AUTOSAR XML (schema 4-0-3)
package /DTC_Component
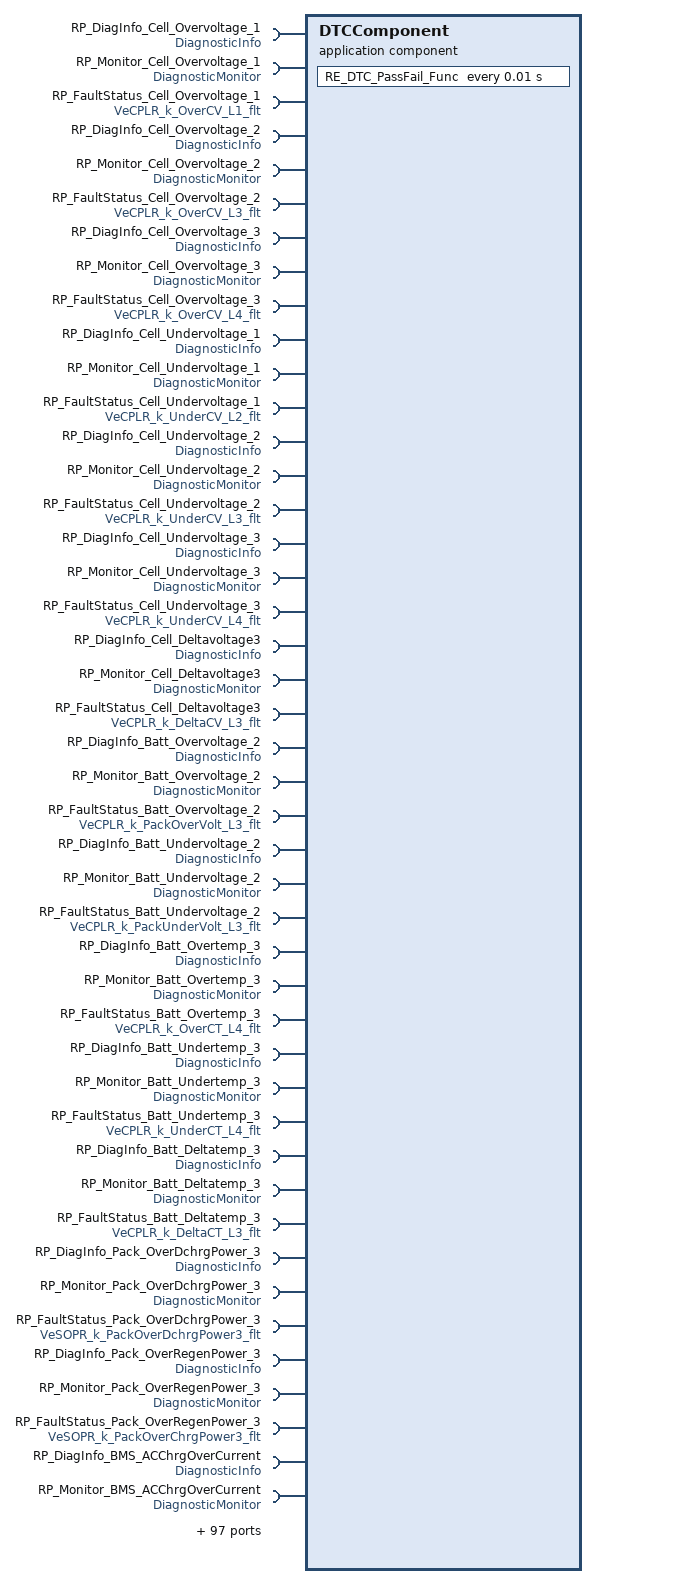
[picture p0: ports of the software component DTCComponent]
  application sw component type DTCComponent
    141 x require port:
      RP_DiagInfo_Cell_Overvoltage_1: required-interface=DiagnosticInfo
      RP_Monitor_Cell_Overvoltage_1: required-interface=DiagnosticMonitor
      RP_FaultStatus_Cell_Overvoltage_1: required-interface=VeCPLR_k_OverCV_L1_flt
      RP_DiagInfo_Cell_Overvoltage_2: required-interface=DiagnosticInfo
      RP_Monitor_Cell_Overvoltage_2: required-interface=DiagnosticMonitor
      RP_FaultStatus_Cell_Overvoltage_2: required-interface=VeCPLR_k_OverCV_L3_flt
      RP_DiagInfo_Cell_Overvoltage_3: required-interface=DiagnosticInfo
      RP_Monitor_Cell_Overvoltage_3: required-interface=DiagnosticMonitor
      RP_FaultStatus_Cell_Overvoltage_3: required-interface=VeCPLR_k_OverCV_L4_flt
      RP_DiagInfo_Cell_Undervoltage_1: required-interface=DiagnosticInfo
      RP_Monitor_Cell_Undervoltage_1: required-interface=DiagnosticMonitor
      RP_FaultStatus_Cell_Undervoltage_1: required-interface=VeCPLR_k_UnderCV_L2_flt
      RP_DiagInfo_Cell_Undervoltage_2: required-interface=DiagnosticInfo
      RP_Monitor_Cell_Undervoltage_2: required-interface=DiagnosticMonitor
      RP_FaultStatus_Cell_Undervoltage_2: required-interface=VeCPLR_k_UnderCV_L3_flt
      RP_DiagInfo_Cell_Undervoltage_3: required-interface=DiagnosticInfo
      RP_Monitor_Cell_Undervoltage_3: required-interface=DiagnosticMonitor
      RP_FaultStatus_Cell_Undervoltage_3: required-interface=VeCPLR_k_UnderCV_L4_flt
      RP_DiagInfo_Cell_Deltavoltage3: required-interface=DiagnosticInfo
      RP_Monitor_Cell_Deltavoltage3: required-interface=DiagnosticMonitor
      RP_FaultStatus_Cell_Deltavoltage3: required-interface=VeCPLR_k_DeltaCV_L3_flt
      RP_DiagInfo_Batt_Overvoltage_2: required-interface=DiagnosticInfo
      RP_Monitor_Batt_Overvoltage_2: required-interface=DiagnosticMonitor
      RP_FaultStatus_Batt_Overvoltage_2: required-interface=VeCPLR_k_PackOverVolt_L3_flt
      RP_DiagInfo_Batt_Undervoltage_2: required-interface=DiagnosticInfo
      RP_Monitor_Batt_Undervoltage_2: required-interface=DiagnosticMonitor
      RP_FaultStatus_Batt_Undervoltage_2: required-interface=VeCPLR_k_PackUnderVolt_L3_flt
      RP_DiagInfo_Batt_Overtemp_3: required-interface=DiagnosticInfo
      RP_Monitor_Batt_Overtemp_3: required-interface=DiagnosticMonitor
      RP_FaultStatus_Batt_Overtemp_3: required-interface=VeCPLR_k_OverCT_L4_flt
      RP_DiagInfo_Batt_Undertemp_3: required-interface=DiagnosticInfo
      RP_Monitor_Batt_Undertemp_3: required-interface=DiagnosticMonitor
      RP_FaultStatus_Batt_Undertemp_3: required-interface=VeCPLR_k_UnderCT_L4_flt
      RP_DiagInfo_Batt_Deltatemp_3: required-interface=DiagnosticInfo
      RP_Monitor_Batt_Deltatemp_3: required-interface=DiagnosticMonitor
      RP_FaultStatus_Batt_Deltatemp_3: required-interface=VeCPLR_k_DeltaCT_L3_flt
      RP_DiagInfo_Pack_OverDchrgPower_3: required-interface=DiagnosticInfo
      RP_Monitor_Pack_OverDchrgPower_3: required-interface=DiagnosticMonitor
      RP_FaultStatus_Pack_OverDchrgPower_3: required-interface=VeSOPR_k_PackOverDchrgPower3_flt
      RP_DiagInfo_Pack_OverRegenPower_3: required-interface=DiagnosticInfo
      RP_Monitor_Pack_OverRegenPower_3: required-interface=DiagnosticMonitor
      RP_FaultStatus_Pack_OverRegenPower_3: required-interface=VeSOPR_k_PackOverChrgPower3_flt
      RP_DiagInfo_BMS_ACChrgOverCurrent: required-interface=DiagnosticInfo
      RP_Monitor_BMS_ACChrgOverCurrent: required-interface=DiagnosticMonitor
      RP_FaultStatus_BMS_ACChrgOverCurrent: required-interface=VeCHMR_k_ChrgOverCurr_level3_flt
      RP_DiagInfo_SOC_low_3: required-interface=DiagnosticInfo
      RP_Monitor_SOC_low_3: required-interface=DiagnosticMonitor
      RP_FaultStatus_SOC_low_3: required-interface=VeSOCR_k_SOC_low3_flt
      RP_DiagInfo_IsoResistor_Error_1: required-interface=DiagnosticInfo
      RP_Monitor_IsoResistor_Error_1: required-interface=DiagnosticMonitor
      RP_FaultStatus_IsoResistor_Error_1: required-interface=VeISLR_k_Isolation_L1_flt
      RP_DiagInfo_IsoResistor_Error_2: required-interface=DiagnosticInfo
      RP_Monitor_IsoResistor_Error_2: required-interface=DiagnosticMonitor
      RP_FaultStatus_IsoResistor_Error_2: required-interface=VeISLR_k_Isolation_L2_flt
      RP_DiagInfo_Crash_states: required-interface=DiagnosticInfo
      RP_Monitor_Crash_states: required-interface=DiagnosticMonitor
      RP_DiagInfo_ThermalRunaway_Error: required-interface=DiagnosticInfo
      RP_Monitor_ThermalRunaway_Error: required-interface=DiagnosticMonitor
      RP_FaultStatus_ThermalRunaway_Error: required-interface=VeCPLR_k_ThermalRunaway_flt
      RP_DiagInfo_BatteryHeatingFault: required-interface=DiagnosticInfo
      RP_Monitor_BatteryHeatingFault: required-interface=DiagnosticMonitor
      RP_FaultStatus_BatteryHeatingFault: required-interface=VeTHMR_k_BatteryHeatingOverCurrt_flt
      RP_DiagInfo_BatteryCoolingFault: required-interface=DiagnosticInfo
      RP_Monitor_BatteryCoolingFault: required-interface=DiagnosticMonitor
      RP_FaultStatus_BatteryCoolingFault: required-interface=VeTHMR_k_BatteryCooling_flt
      RP_DiagInfo_BatteryCircuitOverCurrent: required-interface=DiagnosticInfo
      RP_Monitor_BatteryCircuitOverCurrent: required-interface=DiagnosticMonitor
      RP_FaultStatus_BatteryCircuitOverCurrent: required-interface=VeVSDR_k_HVOverCurrent_flt
      RP_DiagInfo_PosCont_StuckClose: required-interface=DiagnosticInfo
      RP_Monitor_PosCont_StuckClose: required-interface=DiagnosticMonitor
      RP_FaultStatus_PosCont_StuckClose: required-interface=VeCFLR_k_PositiveStuckClose_flt
      RP_DiagInfo_PosCont_StuckOpen: required-interface=DiagnosticInfo
      RP_Monitor_PosCont_StuckOpen: required-interface=DiagnosticMonitor
      RP_FaultStatus_PosCont_StuckOpen: required-interface=VeCFLR_k_PositiveStuckOpen_flt
      RP_DiagInfo_NegCont_StuckClose: required-interface=DiagnosticInfo
      RP_Monitor_NegCont_StuckClose: required-interface=DiagnosticMonitor
      RP_FaultStatus_NegCont_StuckClose: required-interface=VeCFLR_k_NegativeStuckClose_flt
      RP_DiagInfo_NegCont_StuckOpen: required-interface=DiagnosticInfo
      RP_Monitor_NegCont_StuckOpen: required-interface=DiagnosticMonitor
      RP_FaultStatus_NegCont_StuckOpen: required-interface=VeCFLR_k_NegativeStuckOpen_flt
      RP_DiagInfo_PrechrgCont_StuckClose: required-interface=DiagnosticInfo
      RP_Monitor_PrechrgCont_StuckClose: required-interface=DiagnosticMonitor
      RP_FaultStatus_PrechrgCont_StuckClose: required-interface=VeCFLR_k_PrechargeStuckClose_flt
      RP_DiagInfo_PrechrgCont_StuckOpen: required-interface=DiagnosticInfo
      RP_Monitor_PrechrgCont_StuckOpen: required-interface=DiagnosticMonitor
      RP_FaultStatus_PrechrgCont_StuckOpen: required-interface=VeCFLR_k_PrechargeStuckOpen_flt
      RP_DiagInfo_MainFuse1_Open: required-interface=DiagnosticInfo
      RP_Monitor_MainFuse1_Open: required-interface=DiagnosticMonitor
      RP_FaultStatus_MainFuse1_Open: required-interface=VeCFLR_k_MainFuse1Open_flt
      RP_DiagInfo_MainFuse2_Open: required-interface=DiagnosticInfo
      RP_Monitor_MainFuse2_Open: required-interface=DiagnosticMonitor
      RP_FaultStatus_MainFuse2_Open: required-interface=VeCFLR_k_MainFuse2Open_flt
      RP_DiagInfo_VehicleHVInterlockError: required-interface=DiagnosticInfo
      RP_Monitor_VehicleHVInterlockError: required-interface=DiagnosticMonitor
      RP_FaultStatus_VehicleHVInterlockError: required-interface=VeHVIR_k_MainHVIL2_flt
      RP_DiagInfo_BatteryHVInterlockError: required-interface=DiagnosticInfo
      RP_Monitor_BatteryHVInterlockError: required-interface=DiagnosticMonitor
      RP_FaultStatus_BatteryHVInterlockError: required-interface=VeHVIR_k_MainHVIL_flt
      RP_DiagInfo_BatteryInsulationFault: required-interface=DiagnosticInfo
      RP_Monitor_BatteryInsulationFault: required-interface=DiagnosticMonitor
      RP_FaultStatus_BatteryInsulationFault: required-interface=VeISLR_InterIsolation_flt
      RP_DiagInfo_VehicleInsulationFault: required-interface=DiagnosticInfo
      RP_Monitor_VehicleInsulationFault: required-interface=DiagnosticMonitor
      RP_FaultStatus_VehicleInsulationFault: required-interface=VeISLR_ExterIsolation_flt
      RP_DiagInfo_Precharge_Resistor_Open: required-interface=DiagnosticInfo
      RP_Monitor_Precharge_Resistor_Open: required-interface=DiagnosticMonitor
      RP_FaultStatus_Precharge_Resistor_Open: required-interface=VeCFLR_k_PreResistorStuckOpen_flt
      RP_DiagInfo_Precharge_Error: required-interface=DiagnosticInfo
      RP_Monitor_Precharge_Error: required-interface=DiagnosticMonitor
      RP_FaultStatus_Precharge_Error: required-interface=VeCFLR_k_PreChargeFail_flt
      RP_DiagInfo_PrechargeShortCircuit: required-interface=DiagnosticInfo
      RP_Monitor_PrechargeShortCircuit: required-interface=DiagnosticMonitor
      RP_FaultStatus_PrechargeShortCircuit: required-interface=VeCFLR_k_PreChargeOvCur_flt
      RP_DiagInfo_CAN_VCU_error: required-interface=DiagnosticInfo
      RP_Monitor_CAN_VCU_error: required-interface=DiagnosticMonitor
      RP_DiagInfo_CAN_MCUF_Error: required-interface=DiagnosticInfo
      RP_Monitor_CAN_MCUF_Error: required-interface=DiagnosticMonitor
      RP_DiagInfo_CAN_MCUR_Error: required-interface=DiagnosticInfo
      RP_Monitor_CAN_MCUR_Error: required-interface=DiagnosticMonitor
      RP_DiagInfo_CAN_ISG_Error: required-interface=DiagnosticInfo
      RP_Monitor_CAN_ISG_Error: required-interface=DiagnosticMonitor
      RP_DiagInfo_CAN_CDU_Error: required-interface=DiagnosticInfo
      RP_Monitor_CAN_CDU_Error: required-interface=DiagnosticMonitor
      RP_DiagInfo_CAN_CLM_Error: required-interface=DiagnosticInfo
      RP_Monitor_CAN_CLM_Error: required-interface=DiagnosticMonitor
      RP_DiagInfo_CAN_ABM_Error: required-interface=DiagnosticInfo
      RP_Monitor_CAN_ABM_Error: required-interface=DiagnosticMonitor
      RP_DiagInfo_CAN_ICM_Error: required-interface=DiagnosticInfo
      RP_Monitor_CAN_ICM_Error: required-interface=DiagnosticMonitor
      RP_DiagInfo_CAN_TBOX_Error: required-interface=DiagnosticInfo
      RP_Monitor_CAN_TBOX_Error: required-interface=DiagnosticMonitor
      RP_DiagInfo_CAN_BSM_Error: required-interface=DiagnosticInfo
      RP_Monitor_CAN_BSM_Error: required-interface=DiagnosticMonitor
      RP_DiagInfo_CAN_EMS_Error: required-interface=DiagnosticInfo
      RP_Monitor_CAN_EMS_Error: required-interface=DiagnosticMonitor
      RP_DiagInfo_PTCAN_BusOff: required-interface=DiagnosticInfo
      RP_Monitor_PTCAN_BusOff: required-interface=DiagnosticMonitor
      RP_DiagInfo_LV_UnderVoltage: required-interface=DiagnosticInfo
      RP_Monitor_LV_UnderVoltage: required-interface=DiagnosticMonitor
      RP_DiagInfo_LV_OverVoltage: required-interface=DiagnosticInfo
      RP_Monitor_LV_OverVoltage: required-interface=DiagnosticMonitor
    behavior IB_DTC_Cmpnt: data-type-mapping=[VSDR_CodeDataTypeMappingsSet, CLBR_CodeDataTypeMappingsSet, SOER_CodeDataTypeMappingsSet, WorkingDataTypeMappingsSet, ADPR_CodeDataTypeMappingsSet, CHMR_CodeDataTypeMappingsSet, IoHwAbs_CodeDataTypeMappingsSet, THMR_CodeDataTypeMappingsSet, SOPR_CodeDataTypeMappingsSet, CSCR_CodeDataTypeMappingsSet, HMIR_CodeDataTypeMappingsSet, CFLR_CodeDataTypeMappingsSet, DHSR_CodeDataTypeMappingsSet, CPLR_CodeDataTypeMappingsSet, ISLR_CodeDataTypeMappingsSet, DataTypeMappingSet_E2E, SOCR_CodeDataTypeMappingsSet, SOHR_CodeDataTypeMappingsSet, HVSR_CodeDataTypeMappingsSet, HVIR_CodeDataTypeMappingsSet, RTCR_CodeDataTypeMappingSet]
      timing event TimingEvent_DTCs: start-on-event=RE_DTC_PassFail_Func, period=0.01
      runnable RE_DTC_PassFail_Func: symbol=DTC_PassFail_Func
        data-read-access:
          37 x access:
            DRA_VeCPLR_k_OverCV_L1_flt_0: accessed-variable=RP_FaultStatus_Cell_Overvoltage_1.VeCPLR_k_OverCV_L1_flt
            DRA_VeCPLR_k_OverCV_L3_flt_0: accessed-variable=RP_FaultStatus_Cell_Overvoltage_2.VeCPLR_k_OverCV_L3_flt
            DRA_VeCPLR_k_OverCV_L4_flt_0: accessed-variable=RP_FaultStatus_Cell_Overvoltage_3.VeCPLR_k_OverCV_L4_flt
            DRA_VeCPLR_k_UnderCV_L2_flt_0: accessed-variable=RP_FaultStatus_Cell_Undervoltage_1.VeCPLR_k_UnderCV_L2_flt
            DRA_VeCPLR_k_UnderCV_L3_flt_0: accessed-variable=RP_FaultStatus_Cell_Undervoltage_2.VeCPLR_k_UnderCV_L3_flt
            DRA_VeCPLR_k_UnderCV_L4_flt_0: accessed-variable=RP_FaultStatus_Cell_Undervoltage_3.VeCPLR_k_UnderCV_L4_flt
            DRA_VeCPLR_k_DeltaCV_L3_flt_0: accessed-variable=RP_FaultStatus_Cell_Deltavoltage3.VeCPLR_k_DeltaCV_L3_flt
            DRA_VeCPLR_k_PackOverVolt_L3_flt_0: accessed-variable=RP_FaultStatus_Batt_Overvoltage_2.VeCPLR_k_PackOverVolt_L3_flt
            DRA_VeCPLR_k_PackUnderVolt_L3_flt_0: accessed-variable=RP_FaultStatus_Batt_Undervoltage_2.VeCPLR_k_PackUnderVolt_L3_flt
            DRA_VeCPLR_k_OverCT_L4_flt_0: accessed-variable=RP_FaultStatus_Batt_Overtemp_3.VeCPLR_k_OverCT_L4_flt
            DRA_VeCPLR_k_UnderCT_L4_flt_0: accessed-variable=RP_FaultStatus_Batt_Undertemp_3.VeCPLR_k_UnderCT_L4_flt
            DRA_VeCPLR_k_DeltaCT_L3_flt_0: accessed-variable=RP_FaultStatus_Batt_Deltatemp_3.VeCPLR_k_DeltaCT_L3_flt
            DRA_VeSOPR_k_PackOverDchrgPower3_flt_0: accessed-variable=RP_FaultStatus_Pack_OverDchrgPower_3.VeSOPR_k_PackOverDchrgPower3_flt
            DRA_VeSOPR_k_PackOverChrgPower3_flt_0: accessed-variable=RP_FaultStatus_Pack_OverRegenPower_3.VeSOPR_k_PackOverChrgPower3_flt
            DRA_VeCHMR_k_ChrgOverCurr_level3_flt_0: accessed-variable=RP_FaultStatus_BMS_ACChrgOverCurrent.VeCHMR_k_ChrgOverCurr_level3_flt
            DRA_VeSOCR_k_SOC_low3_flt_0: accessed-variable=RP_FaultStatus_SOC_low_3.VeSOCR_k_SOC_low3_flt
            DRA_VeISLR_k_Isolation_L1_flt_0: accessed-variable=RP_FaultStatus_IsoResistor_Error_1.VeISLR_k_Isolation_L1_flt
            DRA_VeISLR_k_Isolation_L2_flt_0: accessed-variable=RP_FaultStatus_IsoResistor_Error_2.VeISLR_k_Isolation_L2_flt
            DRA_VeCPLR_k_ThermalRunaway_flt_0: accessed-variable=RP_FaultStatus_ThermalRunaway_Error.VeCPLR_k_ThermalRunaway_flt
            DRA_VeTHMR_k_BatteryHeatingOverCurrt_flt_0: accessed-variable=RP_FaultStatus_BatteryHeatingFault.VeTHMR_k_BatteryHeatingOverCurrt_flt
            DRA_VeTHMR_k_BatteryCooling_flt_0: accessed-variable=RP_FaultStatus_BatteryCoolingFault.VeTHMR_k_BatteryCooling_flt
            DRA_VeVSDR_k_HVOverCurrent_flt_0: accessed-variable=RP_FaultStatus_BatteryCircuitOverCurrent.VeVSDR_k_HVOverCurrent_flt
            DRA_VeCFLR_k_PositiveStuckClose_flt_0: accessed-variable=RP_FaultStatus_PosCont_StuckClose.VeCFLR_k_PositiveStuckClose_flt
            DRA_VeCFLR_k_PositiveStuckOpen_flt_0: accessed-variable=RP_FaultStatus_PosCont_StuckOpen.VeCFLR_k_PositiveStuckOpen_flt
            DRA_VeCFLR_k_NegativeStuckClose_flt_0: accessed-variable=RP_FaultStatus_NegCont_StuckClose.VeCFLR_k_NegativeStuckClose_flt
            DRA_VeCFLR_k_NegativeStuckOpen_flt_0: accessed-variable=RP_FaultStatus_NegCont_StuckOpen.VeCFLR_k_NegativeStuckOpen_flt
            DRA_VeCFLR_k_PrechargeStuckClose_flt_0: accessed-variable=RP_FaultStatus_PrechrgCont_StuckClose.VeCFLR_k_PrechargeStuckClose_flt
            DRA_VeCFLR_k_PrechargeStuckOpen_flt_0: accessed-variable=RP_FaultStatus_PrechrgCont_StuckOpen.VeCFLR_k_PrechargeStuckOpen_flt
            DRA_VeCFLR_k_MainFuse1Open_flt_0: accessed-variable=RP_FaultStatus_MainFuse1_Open.VeCFLR_k_MainFuse1Open_flt
            DRA_VeCFLR_k_MainFuse2Open_flt_0: accessed-variable=RP_FaultStatus_MainFuse2_Open.VeCFLR_k_MainFuse2Open_flt
            DRA_VeHVIR_k_MainHVIL2_flt_0: accessed-variable=RP_FaultStatus_VehicleHVInterlockError.VeHVIR_k_MainHVIL2_flt
            DRA_VeHVIR_k_MainHVIL_flt_0: accessed-variable=RP_FaultStatus_BatteryHVInterlockError.VeHVIR_k_MainHVIL_flt
            DRA_VeISLR_InterIsolation_flt_0: accessed-variable=RP_FaultStatus_BatteryInsulationFault.VeISLR_InterIsolation_flt
            DRA_VeISLR_ExterIsolation_flt_0: accessed-variable=RP_FaultStatus_VehicleInsulationFault.VeISLR_ExterIsolation_flt
            DRA_VeCFLR_k_PreResistorStuckOpen_flt_0: accessed-variable=RP_FaultStatus_Precharge_Resistor_Open.VeCFLR_k_PreResistorStuckOpen_flt
            DRA_VeCFLR_k_PreChargeFail_flt_0: accessed-variable=RP_FaultStatus_Precharge_Error.VeCFLR_k_PreChargeFail_flt
            DRA_VeCFLR_k_PreChargeOvCur_flt_0: accessed-variable=RP_FaultStatus_PrechargeShortCircuit.VeCFLR_k_PreChargeOvCur_flt
        468 x sync call:
          SSCP_GES_Cell_Overvoltage_1: operation=RP_DiagInfo_Cell_Overvoltage_1.GetEventStatus
          SSCP_GEF_Cell_Overvoltage_1: operation=RP_DiagInfo_Cell_Overvoltage_1.GetEventFailed
          SSCP_GET_Cell_Overvoltage_1: operation=RP_DiagInfo_Cell_Overvoltage_1.GetEventTested
          SSCP_GDTC_Cell_Overvoltage_1: operation=RP_DiagInfo_Cell_Overvoltage_1.GetDTCOfEvent
          SSCP_GFDC_Cell_Overvoltage_1: operation=RP_DiagInfo_Cell_Overvoltage_1.GetFaultDetectionCounter
          SSCP_SES_Cell_Overvoltage_1: operation=RP_Monitor_Cell_Overvoltage_1.SetEventStatus
          SSCP_RES_Cell_Overvoltage_1: operation=RP_Monitor_Cell_Overvoltage_1.ResetEventStatus
          SSCP_PFF_Cell_Overvoltage_1: operation=RP_Monitor_Cell_Overvoltage_1.PrestoreFreezeFrame
          SSCP_CPFF_Cell_Overvoltage_1: operation=RP_Monitor_Cell_Overvoltage_1.ClearPrestoredFreezeFrame
          SSCP_GES_Cell_Overvoltage_2: operation=RP_DiagInfo_Cell_Overvoltage_2.GetEventStatus
          SSCP_GEF_Cell_Overvoltage_2: operation=RP_DiagInfo_Cell_Overvoltage_2.GetEventFailed
          SSCP_GET_Cell_Overvoltage_2: operation=RP_DiagInfo_Cell_Overvoltage_2.GetEventTested
          SSCP_GDTC_Cell_Overvoltage_2: operation=RP_DiagInfo_Cell_Overvoltage_2.GetDTCOfEvent
          SSCP_GFDC_Cell_Overvoltage_2: operation=RP_DiagInfo_Cell_Overvoltage_2.GetFaultDetectionCounter
          SSCP_SES_Cell_Overvoltage_2: operation=RP_Monitor_Cell_Overvoltage_2.SetEventStatus
          SSCP_RES_Cell_Overvoltage_2: operation=RP_Monitor_Cell_Overvoltage_2.ResetEventStatus
          SSCP_PFF_Cell_Overvoltage_2: operation=RP_Monitor_Cell_Overvoltage_2.PrestoreFreezeFrame
          SSCP_CPFF_Cell_Overvoltage_2: operation=RP_Monitor_Cell_Overvoltage_2.ClearPrestoredFreezeFrame
          SSCP_GES_Cell_Overvoltage_3: operation=RP_DiagInfo_Cell_Overvoltage_3.GetEventStatus
          SSCP_GEF_Cell_Overvoltage_3: operation=RP_DiagInfo_Cell_Overvoltage_3.GetEventFailed
          SSCP_GET_Cell_Overvoltage_3: operation=RP_DiagInfo_Cell_Overvoltage_3.GetEventTested
          SSCP_GDTC_Cell_Overvoltage_3: operation=RP_DiagInfo_Cell_Overvoltage_3.GetDTCOfEvent
          SSCP_GFDC_Cell_Overvoltage_3: operation=RP_DiagInfo_Cell_Overvoltage_3.GetFaultDetectionCounter
          SSCP_SES_Cell_Overvoltage_3: operation=RP_Monitor_Cell_Overvoltage_3.SetEventStatus
          SSCP_RES_Cell_Overvoltage_3: operation=RP_Monitor_Cell_Overvoltage_3.ResetEventStatus
          SSCP_PFF_Cell_Overvoltage_3: operation=RP_Monitor_Cell_Overvoltage_3.PrestoreFreezeFrame
          SSCP_CPFF_Cell_Overvoltage_3: operation=RP_Monitor_Cell_Overvoltage_3.ClearPrestoredFreezeFrame
          SSCP_GES_Cell_Undervoltage_1: operation=RP_DiagInfo_Cell_Undervoltage_1.GetEventStatus
          SSCP_GEF_Cell_Undervoltage_1: operation=RP_DiagInfo_Cell_Undervoltage_1.GetEventFailed
          SSCP_GET_Cell_Undervoltage_1: operation=RP_DiagInfo_Cell_Undervoltage_1.GetEventTested
          SSCP_GDTC_Cell_Undervoltage_1: operation=RP_DiagInfo_Cell_Undervoltage_1.GetDTCOfEvent
          SSCP_GFDC_Cell_Undervoltage_1: operation=RP_DiagInfo_Cell_Undervoltage_1.GetFaultDetectionCounter
          SSCP_SES_Cell_Undervoltage_1: operation=RP_Monitor_Cell_Undervoltage_1.SetEventStatus
          SSCP_RES_Cell_Undervoltage_1: operation=RP_Monitor_Cell_Undervoltage_1.ResetEventStatus
          SSCP_PFF_Cell_Undervoltage_1: operation=RP_Monitor_Cell_Undervoltage_1.PrestoreFreezeFrame
          SSCP_CPFF_Cell_Undervoltage_1: operation=RP_Monitor_Cell_Undervoltage_1.ClearPrestoredFreezeFrame
          SSCP_GES_Cell_Undervoltage_2: operation=RP_DiagInfo_Cell_Undervoltage_2.GetEventStatus
          SSCP_GEF_Cell_Undervoltage_2: operation=RP_DiagInfo_Cell_Undervoltage_2.GetEventFailed
          SSCP_GET_Cell_Undervoltage_2: operation=RP_DiagInfo_Cell_Undervoltage_2.GetEventTested
          SSCP_GDTC_Cell_Undervoltage_2: operation=RP_DiagInfo_Cell_Undervoltage_2.GetDTCOfEvent
          SSCP_GFDC_Cell_Undervoltage_2: operation=RP_DiagInfo_Cell_Undervoltage_2.GetFaultDetectionCounter
          SSCP_SES_Cell_Undervoltage_2: operation=RP_Monitor_Cell_Undervoltage_2.SetEventStatus
          SSCP_RES_Cell_Undervoltage_2: operation=RP_Monitor_Cell_Undervoltage_2.ResetEventStatus
          SSCP_PFF_Cell_Undervoltage_2: operation=RP_Monitor_Cell_Undervoltage_2.PrestoreFreezeFrame
          SSCP_CPFF_Cell_Undervoltage_2: operation=RP_Monitor_Cell_Undervoltage_2.ClearPrestoredFreezeFrame
          SSCP_GES_Cell_Undervoltage_3: operation=RP_DiagInfo_Cell_Undervoltage_3.GetEventStatus
          SSCP_GEF_Cell_Undervoltage_3: operation=RP_DiagInfo_Cell_Undervoltage_3.GetEventFailed
          SSCP_GET_Cell_Undervoltage_3: operation=RP_DiagInfo_Cell_Undervoltage_3.GetEventTested
          SSCP_GDTC_Cell_Undervoltage_3: operation=RP_DiagInfo_Cell_Undervoltage_3.GetDTCOfEvent
          SSCP_GFDC_Cell_Undervoltage_3: operation=RP_DiagInfo_Cell_Undervoltage_3.GetFaultDetectionCounter
          SSCP_SES_Cell_Undervoltage_3: operation=RP_Monitor_Cell_Undervoltage_3.SetEventStatus
          SSCP_RES_Cell_Undervoltage_3: operation=RP_Monitor_Cell_Undervoltage_3.ResetEventStatus
          SSCP_PFF_Cell_Undervoltage_3: operation=RP_Monitor_Cell_Undervoltage_3.PrestoreFreezeFrame
          SSCP_CPFF_Cell_Undervoltage_3: operation=RP_Monitor_Cell_Undervoltage_3.ClearPrestoredFreezeFrame
          SSCP_GES_Cell_Deltavoltage3: operation=RP_DiagInfo_Cell_Deltavoltage3.GetEventStatus
          SSCP_GEF_Cell_Deltavoltage3: operation=RP_DiagInfo_Cell_Deltavoltage3.GetEventFailed
          SSCP_GET_Cell_Deltavoltage3: operation=RP_DiagInfo_Cell_Deltavoltage3.GetEventTested
          SSCP_GDTC_Cell_Deltavoltage3: operation=RP_DiagInfo_Cell_Deltavoltage3.GetDTCOfEvent
          SSCP_GFDC_Cell_Deltavoltage3: operation=RP_DiagInfo_Cell_Deltavoltage3.GetFaultDetectionCounter
          SSCP_SES_Cell_Deltavoltage3: operation=RP_Monitor_Cell_Deltavoltage3.SetEventStatus
          SSCP_RES_Cell_Deltavoltage3: operation=RP_Monitor_Cell_Deltavoltage3.ResetEventStatus
          SSCP_PFF_Cell_Deltavoltage3: operation=RP_Monitor_Cell_Deltavoltage3.PrestoreFreezeFrame
          SSCP_CPFF_Cell_Deltavoltage3: operation=RP_Monitor_Cell_Deltavoltage3.ClearPrestoredFreezeFrame
          SSCP_GES_Batt_Overvoltage_2: operation=RP_DiagInfo_Batt_Overvoltage_2.GetEventStatus
          SSCP_GEF_Batt_Overvoltage_2: operation=RP_DiagInfo_Batt_Overvoltage_2.GetEventFailed
          SSCP_GET_Batt_Overvoltage_2: operation=RP_DiagInfo_Batt_Overvoltage_2.GetEventTested
          SSCP_GDTC_Batt_Overvoltage_2: operation=RP_DiagInfo_Batt_Overvoltage_2.GetDTCOfEvent
          SSCP_GFDC_Batt_Overvoltage_2: operation=RP_DiagInfo_Batt_Overvoltage_2.GetFaultDetectionCounter
          SSCP_SES_Batt_Overvoltage_2: operation=RP_Monitor_Batt_Overvoltage_2.SetEventStatus
          SSCP_RES_Batt_Overvoltage_2: operation=RP_Monitor_Batt_Overvoltage_2.ResetEventStatus
          SSCP_PFF_Batt_Overvoltage_2: operation=RP_Monitor_Batt_Overvoltage_2.PrestoreFreezeFrame
          SSCP_CPFF_Batt_Overvoltage_2: operation=RP_Monitor_Batt_Overvoltage_2.ClearPrestoredFreezeFrame
          SSCP_GES_Batt_Undervoltage_2: operation=RP_DiagInfo_Batt_Undervoltage_2.GetEventStatus
          SSCP_GEF_Batt_Undervoltage_2: operation=RP_DiagInfo_Batt_Undervoltage_2.GetEventFailed
          SSCP_GET_Batt_Undervoltage_2: operation=RP_DiagInfo_Batt_Undervoltage_2.GetEventTested
          SSCP_GDTC_Batt_Undervoltage_2: operation=RP_DiagInfo_Batt_Undervoltage_2.GetDTCOfEvent
          SSCP_GFDC_Batt_Undervoltage_2: operation=RP_DiagInfo_Batt_Undervoltage_2.GetFaultDetectionCounter
          SSCP_SES_Batt_Undervoltage_2: operation=RP_Monitor_Batt_Undervoltage_2.SetEventStatus
          SSCP_RES_Batt_Undervoltage_2: operation=RP_Monitor_Batt_Undervoltage_2.ResetEventStatus
          SSCP_PFF_Batt_Undervoltage_2: operation=RP_Monitor_Batt_Undervoltage_2.PrestoreFreezeFrame
          SSCP_CPFF_Batt_Undervoltage_2: operation=RP_Monitor_Batt_Undervoltage_2.ClearPrestoredFreezeFrame
          SSCP_GES_Batt_Overtemp_3: operation=RP_DiagInfo_Batt_Overtemp_3.GetEventStatus
          SSCP_GEF_Batt_Overtemp_3: operation=RP_DiagInfo_Batt_Overtemp_3.GetEventFailed
          SSCP_GET_Batt_Overtemp_3: operation=RP_DiagInfo_Batt_Overtemp_3.GetEventTested
          SSCP_GDTC_Batt_Overtemp_3: operation=RP_DiagInfo_Batt_Overtemp_3.GetDTCOfEvent
          SSCP_GFDC_Batt_Overtemp_3: operation=RP_DiagInfo_Batt_Overtemp_3.GetFaultDetectionCounter
          SSCP_SES_Batt_Overtemp_3: operation=RP_Monitor_Batt_Overtemp_3.SetEventStatus
          SSCP_RES_Batt_Overtemp_3: operation=RP_Monitor_Batt_Overtemp_3.ResetEventStatus
          SSCP_PFF_Batt_Overtemp_3: operation=RP_Monitor_Batt_Overtemp_3.PrestoreFreezeFrame
          SSCP_CPFF_Batt_Overtemp_3: operation=RP_Monitor_Batt_Overtemp_3.ClearPrestoredFreezeFrame
          SSCP_GES_Batt_Undertemp_3: operation=RP_DiagInfo_Batt_Undertemp_3.GetEventStatus
          SSCP_GEF_Batt_Undertemp_3: operation=RP_DiagInfo_Batt_Undertemp_3.GetEventFailed
          SSCP_GET_Batt_Undertemp_3: operation=RP_DiagInfo_Batt_Undertemp_3.GetEventTested
          SSCP_GDTC_Batt_Undertemp_3: operation=RP_DiagInfo_Batt_Undertemp_3.GetDTCOfEvent
          SSCP_GFDC_Batt_Undertemp_3: operation=RP_DiagInfo_Batt_Undertemp_3.GetFaultDetectionCounter
          SSCP_SES_Batt_Undertemp_3: operation=RP_Monitor_Batt_Undertemp_3.SetEventStatus
          SSCP_RES_Batt_Undertemp_3: operation=RP_Monitor_Batt_Undertemp_3.ResetEventStatus
          SSCP_PFF_Batt_Undertemp_3: operation=RP_Monitor_Batt_Undertemp_3.PrestoreFreezeFrame
          SSCP_CPFF_Batt_Undertemp_3: operation=RP_Monitor_Batt_Undertemp_3.ClearPrestoredFreezeFrame
          SSCP_GES_Batt_Deltatemp_3: operation=RP_DiagInfo_Batt_Deltatemp_3.GetEventStatus
          SSCP_GEF_Batt_Deltatemp_3: operation=RP_DiagInfo_Batt_Deltatemp_3.GetEventFailed
          SSCP_GET_Batt_Deltatemp_3: operation=RP_DiagInfo_Batt_Deltatemp_3.GetEventTested
          SSCP_GDTC_Batt_Deltatemp_3: operation=RP_DiagInfo_Batt_Deltatemp_3.GetDTCOfEvent
          SSCP_GFDC_Batt_Deltatemp_3: operation=RP_DiagInfo_Batt_Deltatemp_3.GetFaultDetectionCounter
          SSCP_SES_Batt_Deltatemp_3: operation=RP_Monitor_Batt_Deltatemp_3.SetEventStatus
          SSCP_RES_Batt_Deltatemp_3: operation=RP_Monitor_Batt_Deltatemp_3.ResetEventStatus
          SSCP_PFF_Batt_Deltatemp_3: operation=RP_Monitor_Batt_Deltatemp_3.PrestoreFreezeFrame
          SSCP_CPFF_Batt_Deltatemp_3: operation=RP_Monitor_Batt_Deltatemp_3.ClearPrestoredFreezeFrame
          SSCP_GES_Pack_OverDchrgPower_3: operation=RP_DiagInfo_Pack_OverDchrgPower_3.GetEventStatus
          SSCP_GEF_Pack_OverDchrgPower_3: operation=RP_DiagInfo_Pack_OverDchrgPower_3.GetEventFailed
          SSCP_GET_Pack_OverDchrgPower_3: operation=RP_DiagInfo_Pack_OverDchrgPower_3.GetEventTested
          SSCP_GDTC_Pack_OverDchrgPower_3: operation=RP_DiagInfo_Pack_OverDchrgPower_3.GetDTCOfEvent
          SSCP_GFDC_Pack_OverDchrgPower_3: operation=RP_DiagInfo_Pack_OverDchrgPower_3.GetFaultDetectionCounter
          SSCP_SES_Pack_OverDchrgPower_3: operation=RP_Monitor_Pack_OverDchrgPower_3.SetEventStatus
          SSCP_RES_Pack_OverDchrgPower_3: operation=RP_Monitor_Pack_OverDchrgPower_3.ResetEventStatus
          SSCP_PFF_Pack_OverDchrgPower_3: operation=RP_Monitor_Pack_OverDchrgPower_3.PrestoreFreezeFrame
          SSCP_CPFF_Pack_OverDchrgPower_3: operation=RP_Monitor_Pack_OverDchrgPower_3.ClearPrestoredFreezeFrame
          SSCP_GES_Pack_OverRegenPower_3: operation=RP_DiagInfo_Pack_OverRegenPower_3.GetEventStatus
          SSCP_GEF_Pack_OverRegenPower_3: operation=RP_DiagInfo_Pack_OverRegenPower_3.GetEventFailed
          SSCP_GET_Pack_OverRegenPower_3: operation=RP_DiagInfo_Pack_OverRegenPower_3.GetEventTested
          SSCP_GDTC_Pack_OverRegenPower_3: operation=RP_DiagInfo_Pack_OverRegenPower_3.GetDTCOfEvent
          SSCP_GFDC_Pack_OverRegenPower_3: operation=RP_DiagInfo_Pack_OverRegenPower_3.GetFaultDetectionCounter
          SSCP_SES_Pack_OverRegenPower_3: operation=RP_Monitor_Pack_OverRegenPower_3.SetEventStatus
          SSCP_RES_Pack_OverRegenPower_3: operation=RP_Monitor_Pack_OverRegenPower_3.ResetEventStatus
          SSCP_PFF_Pack_OverRegenPower_3: operation=RP_Monitor_Pack_OverRegenPower_3.PrestoreFreezeFrame
          SSCP_CPFF_Pack_OverRegenPower_3: operation=RP_Monitor_Pack_OverRegenPower_3.ClearPrestoredFreezeFrame
          SSCP_GES_BMS_ACChrgOverCurrent: operation=RP_DiagInfo_BMS_ACChrgOverCurrent.GetEventStatus
          SSCP_GEF_BMS_ACChrgOverCurrent: operation=RP_DiagInfo_BMS_ACChrgOverCurrent.GetEventFailed
          SSCP_GET_BMS_ACChrgOverCurrent: operation=RP_DiagInfo_BMS_ACChrgOverCurrent.GetEventTested
          SSCP_GDTC_BMS_ACChrgOverCurrent: operation=RP_DiagInfo_BMS_ACChrgOverCurrent.GetDTCOfEvent
          SSCP_GFDC_BMS_ACChrgOverCurrent: operation=RP_DiagInfo_BMS_ACChrgOverCurrent.GetFaultDetectionCounter
          SSCP_SES_BMS_ACChrgOverCurrent: operation=RP_Monitor_BMS_ACChrgOverCurrent.SetEventStatus
          SSCP_RES_BMS_ACChrgOverCurrent: operation=RP_Monitor_BMS_ACChrgOverCurrent.ResetEventStatus
          SSCP_PFF_BMS_ACChrgOverCurrent: operation=RP_Monitor_BMS_ACChrgOverCurrent.PrestoreFreezeFrame
          SSCP_CPFF_BMS_ACChrgOverCurrent: operation=RP_Monitor_BMS_ACChrgOverCurrent.ClearPrestoredFreezeFrame
          SSCP_GES_SOC_low_3: operation=RP_DiagInfo_SOC_low_3.GetEventStatus
          SSCP_GEF_SOC_low_3: operation=RP_DiagInfo_SOC_low_3.GetEventFailed
          SSCP_GET_SOC_low_3: operation=RP_DiagInfo_SOC_low_3.GetEventTested
          SSCP_GDTC_SOC_low_3: operation=RP_DiagInfo_SOC_low_3.GetDTCOfEvent
          SSCP_GFDC_SOC_low_3: operation=RP_DiagInfo_SOC_low_3.GetFaultDetectionCounter
          SSCP_SES_SOC_low_3: operation=RP_Monitor_SOC_low_3.SetEventStatus
          SSCP_RES_SOC_low_3: operation=RP_Monitor_SOC_low_3.ResetEventStatus
          SSCP_PFF_SOC_low_3: operation=RP_Monitor_SOC_low_3.PrestoreFreezeFrame
          SSCP_CPFF_SOC_low_3: operation=RP_Monitor_SOC_low_3.ClearPrestoredFreezeFrame
          SSCP_GES_IsoResistor_Error_1: operation=RP_DiagInfo_IsoResistor_Error_1.GetEventStatus
          SSCP_GEF_IsoResistor_Error_1: operation=RP_DiagInfo_IsoResistor_Error_1.GetEventFailed
          SSCP_GET_IsoResistor_Error_1: operation=RP_DiagInfo_IsoResistor_Error_1.GetEventTested
          SSCP_GDTC_IsoResistor_Error_1: operation=RP_DiagInfo_IsoResistor_Error_1.GetDTCOfEvent
          SSCP_GFDC_IsoResistor_Error_1: operation=RP_DiagInfo_IsoResistor_Error_1.GetFaultDetectionCounter
          SSCP_SES_IsoResistor_Error_1: operation=RP_Monitor_IsoResistor_Error_1.SetEventStatus
          SSCP_RES_IsoResistor_Error_1: operation=RP_Monitor_IsoResistor_Error_1.ResetEventStatus
          SSCP_PFF_IsoResistor_Error_1: operation=RP_Monitor_IsoResistor_Error_1.PrestoreFreezeFrame
          SSCP_CPFF_IsoResistor_Error_1: operation=RP_Monitor_IsoResistor_Error_1.ClearPrestoredFreezeFrame
          SSCP_GES_IsoResistor_Error_2: operation=RP_DiagInfo_IsoResistor_Error_2.GetEventStatus
          SSCP_GEF_IsoResistor_Error_2: operation=RP_DiagInfo_IsoResistor_Error_2.GetEventFailed
          SSCP_GET_IsoResistor_Error_2: operation=RP_DiagInfo_IsoResistor_Error_2.GetEventTested
          SSCP_GDTC_IsoResistor_Error_2: operation=RP_DiagInfo_IsoResistor_Error_2.GetDTCOfEvent
          SSCP_GFDC_IsoResistor_Error_2: operation=RP_DiagInfo_IsoResistor_Error_2.GetFaultDetectionCounter
          SSCP_SES_IsoResistor_Error_2: operation=RP_Monitor_IsoResistor_Error_2.SetEventStatus
          SSCP_RES_IsoResistor_Error_2: operation=RP_Monitor_IsoResistor_Error_2.ResetEventStatus
          SSCP_PFF_IsoResistor_Error_2: operation=RP_Monitor_IsoResistor_Error_2.PrestoreFreezeFrame
          SSCP_CPFF_IsoResistor_Error_2: operation=RP_Monitor_IsoResistor_Error_2.ClearPrestoredFreezeFrame
          SSCP_GES_Crash_states: operation=RP_DiagInfo_Crash_states.GetEventStatus
          SSCP_GEF_Crash_states: operation=RP_DiagInfo_Crash_states.GetEventFailed
          SSCP_GET_Crash_states: operation=RP_DiagInfo_Crash_states.GetEventTested
          SSCP_GDTC_Crash_states: operation=RP_DiagInfo_Crash_states.GetDTCOfEvent
          SSCP_GFDC_Crash_states: operation=RP_DiagInfo_Crash_states.GetFaultDetectionCounter
          SSCP_SES_Crash_states: operation=RP_Monitor_Crash_states.SetEventStatus
          SSCP_RES_Crash_states: operation=RP_Monitor_Crash_states.ResetEventStatus
          SSCP_PFF_Crash_states: operation=RP_Monitor_Crash_states.PrestoreFreezeFrame
          SSCP_CPFF_Crash_states: operation=RP_Monitor_Crash_states.ClearPrestoredFreezeFrame
          SSCP_GES_ThermalRunaway_Error: operation=RP_DiagInfo_ThermalRunaway_Error.GetEventStatus
          SSCP_GEF_ThermalRunaway_Error: operation=RP_DiagInfo_ThermalRunaway_Error.GetEventFailed
          SSCP_GET_ThermalRunaway_Error: operation=RP_DiagInfo_ThermalRunaway_Error.GetEventTested
          SSCP_GDTC_ThermalRunaway_Error: operation=RP_DiagInfo_ThermalRunaway_Error.GetDTCOfEvent
          SSCP_GFDC_ThermalRunaway_Error: operation=RP_DiagInfo_ThermalRunaway_Error.GetFaultDetectionCounter
          SSCP_SES_ThermalRunaway_Error: operation=RP_Monitor_ThermalRunaway_Error.SetEventStatus
          SSCP_RES_ThermalRunaway_Error: operation=RP_Monitor_ThermalRunaway_Error.ResetEventStatus
          SSCP_PFF_ThermalRunaway_Error: operation=RP_Monitor_ThermalRunaway_Error.PrestoreFreezeFrame
          SSCP_CPFF_ThermalRunaway_Error: operation=RP_Monitor_ThermalRunaway_Error.ClearPrestoredFreezeFrame
          SSCP_GES_BatteryHeatingFault: operation=RP_DiagInfo_BatteryHeatingFault.GetEventStatus
          SSCP_GEF_BatteryHeatingFault: operation=RP_DiagInfo_BatteryHeatingFault.GetEventFailed
          SSCP_GET_BatteryHeatingFault: operation=RP_DiagInfo_BatteryHeatingFault.GetEventTested
          SSCP_GDTC_BatteryHeatingFault: operation=RP_DiagInfo_BatteryHeatingFault.GetDTCOfEvent
          SSCP_GFDC_BatteryHeatingFault: operation=RP_DiagInfo_BatteryHeatingFault.GetFaultDetectionCounter
          SSCP_SES_BatteryHeatingFault: operation=RP_Monitor_BatteryHeatingFault.SetEventStatus
          SSCP_RES_BatteryHeatingFault: operation=RP_Monitor_BatteryHeatingFault.ResetEventStatus
          SSCP_PFF_BatteryHeatingFault: operation=RP_Monitor_BatteryHeatingFault.PrestoreFreezeFrame
          SSCP_CPFF_BatteryHeatingFault: operation=RP_Monitor_BatteryHeatingFault.ClearPrestoredFreezeFrame
          SSCP_GES_BatteryCoolingFault: operation=RP_DiagInfo_BatteryCoolingFault.GetEventStatus
          SSCP_GEF_BatteryCoolingFault: operation=RP_DiagInfo_BatteryCoolingFault.GetEventFailed
          SSCP_GET_BatteryCoolingFault: operation=RP_DiagInfo_BatteryCoolingFault.GetEventTested
          SSCP_GDTC_BatteryCoolingFault: operation=RP_DiagInfo_BatteryCoolingFault.GetDTCOfEvent
          SSCP_GFDC_BatteryCoolingFault: operation=RP_DiagInfo_BatteryCoolingFault.GetFaultDetectionCounter
          SSCP_SES_BatteryCoolingFault: operation=RP_Monitor_BatteryCoolingFault.SetEventStatus
          SSCP_RES_BatteryCoolingFault: operation=RP_Monitor_BatteryCoolingFault.ResetEventStatus
          SSCP_PFF_BatteryCoolingFault: operation=RP_Monitor_BatteryCoolingFault.PrestoreFreezeFrame
          SSCP_CPFF_BatteryCoolingFault: operation=RP_Monitor_BatteryCoolingFault.ClearPrestoredFreezeFrame
          SSCP_GES_BatteryCircuitOverCurrent: operation=RP_DiagInfo_BatteryCircuitOverCurrent.GetEventStatus
          SSCP_GEF_BatteryCircuitOverCurrent: operation=RP_DiagInfo_BatteryCircuitOverCurrent.GetEventFailed
          SSCP_GET_BatteryCircuitOverCurrent: operation=RP_DiagInfo_BatteryCircuitOverCurrent.GetEventTested
          SSCP_GDTC_BatteryCircuitOverCurrent: operation=RP_DiagInfo_BatteryCircuitOverCurrent.GetDTCOfEvent
          SSCP_GFDC_BatteryCircuitOverCurrent: operation=RP_DiagInfo_BatteryCircuitOverCurrent.GetFaultDetectionCounter
          SSCP_SES_BatteryCircuitOverCurrent: operation=RP_Monitor_BatteryCircuitOverCurrent.SetEventStatus
          SSCP_RES_BatteryCircuitOverCurrent: operation=RP_Monitor_BatteryCircuitOverCurrent.ResetEventStatus
          SSCP_PFF_BatteryCircuitOverCurrent: operation=RP_Monitor_BatteryCircuitOverCurrent.PrestoreFreezeFrame
          SSCP_CPFF_BatteryCircuitOverCurrent: operation=RP_Monitor_BatteryCircuitOverCurrent.ClearPrestoredFreezeFrame
          SSCP_GES_PosCont_StuckClose: operation=RP_DiagInfo_PosCont_StuckClose.GetEventStatus
          SSCP_GEF_PosCont_StuckClose: operation=RP_DiagInfo_PosCont_StuckClose.GetEventFailed
          SSCP_GET_PosCont_StuckClose: operation=RP_DiagInfo_PosCont_StuckClose.GetEventTested
          SSCP_GDTC_PosCont_StuckClose: operation=RP_DiagInfo_PosCont_StuckClose.GetDTCOfEvent
          SSCP_GFDC_PosCont_StuckClose: operation=RP_DiagInfo_PosCont_StuckClose.GetFaultDetectionCounter
          SSCP_SES_PosCont_StuckClose: operation=RP_Monitor_PosCont_StuckClose.SetEventStatus
          SSCP_RES_PosCont_StuckClose: operation=RP_Monitor_PosCont_StuckClose.ResetEventStatus
          SSCP_PFF_PosCont_StuckClose: operation=RP_Monitor_PosCont_StuckClose.PrestoreFreezeFrame
          SSCP_CPFF_PosCont_StuckClose: operation=RP_Monitor_PosCont_StuckClose.ClearPrestoredFreezeFrame
          SSCP_GES_PosCont_StuckOpen: operation=RP_DiagInfo_PosCont_StuckOpen.GetEventStatus
          SSCP_GEF_PosCont_StuckOpen: operation=RP_DiagInfo_PosCont_StuckOpen.GetEventFailed
          SSCP_GET_PosCont_StuckOpen: operation=RP_DiagInfo_PosCont_StuckOpen.GetEventTested
          SSCP_GDTC_PosCont_StuckOpen: operation=RP_DiagInfo_PosCont_StuckOpen.GetDTCOfEvent
          SSCP_GFDC_PosCont_StuckOpen: operation=RP_DiagInfo_PosCont_StuckOpen.GetFaultDetectionCounter
          SSCP_SES_PosCont_StuckOpen: operation=RP_Monitor_PosCont_StuckOpen.SetEventStatus
          SSCP_RES_PosCont_StuckOpen: operation=RP_Monitor_PosCont_StuckOpen.ResetEventStatus
          SSCP_PFF_PosCont_StuckOpen: operation=RP_Monitor_PosCont_StuckOpen.PrestoreFreezeFrame
          SSCP_CPFF_PosCont_StuckOpen: operation=RP_Monitor_PosCont_StuckOpen.ClearPrestoredFreezeFrame
          SSCP_GES_NegCont_StuckClose: operation=RP_DiagInfo_NegCont_StuckClose.GetEventStatus
          SSCP_GEF_NegCont_StuckClose: operation=RP_DiagInfo_NegCont_StuckClose.GetEventFailed
          SSCP_GET_NegCont_StuckClose: operation=RP_DiagInfo_NegCont_StuckClose.GetEventTested
          SSCP_GDTC_NegCont_StuckClose: operation=RP_DiagInfo_NegCont_StuckClose.GetDTCOfEvent
          SSCP_GFDC_NegCont_StuckClose: operation=RP_DiagInfo_NegCont_StuckClose.GetFaultDetectionCounter
          SSCP_SES_NegCont_StuckClose: operation=RP_Monitor_NegCont_StuckClose.SetEventStatus
          SSCP_RES_NegCont_StuckClose: operation=RP_Monitor_NegCont_StuckClose.ResetEventStatus
          SSCP_PFF_NegCont_StuckClose: operation=RP_Monitor_NegCont_StuckClose.PrestoreFreezeFrame
          SSCP_CPFF_NegCont_StuckClose: operation=RP_Monitor_NegCont_StuckClose.ClearPrestoredFreezeFrame
          SSCP_GES_NegCont_StuckOpen: operation=RP_DiagInfo_NegCont_StuckOpen.GetEventStatus
          SSCP_GEF_NegCont_StuckOpen: operation=RP_DiagInfo_NegCont_StuckOpen.GetEventFailed
          SSCP_GET_NegCont_StuckOpen: operation=RP_DiagInfo_NegCont_StuckOpen.GetEventTested
          SSCP_GDTC_NegCont_StuckOpen: operation=RP_DiagInfo_NegCont_StuckOpen.GetDTCOfEvent
          SSCP_GFDC_NegCont_StuckOpen: operation=RP_DiagInfo_NegCont_StuckOpen.GetFaultDetectionCounter
          SSCP_SES_NegCont_StuckOpen: operation=RP_Monitor_NegCont_StuckOpen.SetEventStatus
          SSCP_RES_NegCont_StuckOpen: operation=RP_Monitor_NegCont_StuckOpen.ResetEventStatus
          SSCP_PFF_NegCont_StuckOpen: operation=RP_Monitor_NegCont_StuckOpen.PrestoreFreezeFrame
          SSCP_CPFF_NegCont_StuckOpen: operation=RP_Monitor_NegCont_StuckOpen.ClearPrestoredFreezeFrame
          SSCP_GES_PrechrgCont_StuckClose: operation=RP_DiagInfo_PrechrgCont_StuckClose.GetEventStatus
          SSCP_GEF_PrechrgCont_StuckClose: operation=RP_DiagInfo_PrechrgCont_StuckClose.GetEventFailed
          SSCP_GET_PrechrgCont_StuckClose: operation=RP_DiagInfo_PrechrgCont_StuckClose.GetEventTested
          SSCP_GDTC_PrechrgCont_StuckClose: operation=RP_DiagInfo_PrechrgCont_StuckClose.GetDTCOfEvent
          SSCP_GFDC_PrechrgCont_StuckClose: operation=RP_DiagInfo_PrechrgCont_StuckClose.GetFaultDetectionCounter
          SSCP_SES_PrechrgCont_StuckClose: operation=RP_Monitor_PrechrgCont_StuckClose.SetEventStatus
          SSCP_RES_PrechrgCont_StuckClose: operation=RP_Monitor_PrechrgCont_StuckClose.ResetEventStatus
          SSCP_PFF_PrechrgCont_StuckClose: operation=RP_Monitor_PrechrgCont_StuckClose.PrestoreFreezeFrame
          SSCP_CPFF_PrechrgCont_StuckClose: operation=RP_Monitor_PrechrgCont_StuckClose.ClearPrestoredFreezeFrame
          SSCP_GES_PrechrgCont_StuckOpen: operation=RP_DiagInfo_PrechrgCont_StuckOpen.GetEventStatus
          SSCP_GEF_PrechrgCont_StuckOpen: operation=RP_DiagInfo_PrechrgCont_StuckOpen.GetEventFailed
          SSCP_GET_PrechrgCont_StuckOpen: operation=RP_DiagInfo_PrechrgCont_StuckOpen.GetEventTested
          SSCP_GDTC_PrechrgCont_StuckOpen: operation=RP_DiagInfo_PrechrgCont_StuckOpen.GetDTCOfEvent
          SSCP_GFDC_PrechrgCont_StuckOpen: operation=RP_DiagInfo_PrechrgCont_StuckOpen.GetFaultDetectionCounter
          SSCP_SES_PrechrgCont_StuckOpen: operation=RP_Monitor_PrechrgCont_StuckOpen.SetEventStatus
          SSCP_RES_PrechrgCont_StuckOpen: operation=RP_Monitor_PrechrgCont_StuckOpen.ResetEventStatus
          SSCP_PFF_PrechrgCont_StuckOpen: operation=RP_Monitor_PrechrgCont_StuckOpen.PrestoreFreezeFrame
          SSCP_CPFF_PrechrgCont_StuckOpen: operation=RP_Monitor_PrechrgCont_StuckOpen.ClearPrestoredFreezeFrame
          SSCP_GES_MainFuse1_Open: operation=RP_DiagInfo_MainFuse1_Open.GetEventStatus
          SSCP_GEF_MainFuse1_Open: operation=RP_DiagInfo_MainFuse1_Open.GetEventFailed
          SSCP_GET_MainFuse1_Open: operation=RP_DiagInfo_MainFuse1_Open.GetEventTested
          SSCP_GDTC_MainFuse1_Open: operation=RP_DiagInfo_MainFuse1_Open.GetDTCOfEvent
          SSCP_GFDC_MainFuse1_Open: operation=RP_DiagInfo_MainFuse1_Open.GetFaultDetectionCounter
          SSCP_SES_MainFuse1_Open: operation=RP_Monitor_MainFuse1_Open.SetEventStatus
          SSCP_RES_MainFuse1_Open: operation=RP_Monitor_MainFuse1_Open.ResetEventStatus
          SSCP_PFF_MainFuse1_Open: operation=RP_Monitor_MainFuse1_Open.PrestoreFreezeFrame
          SSCP_CPFF_MainFuse1_Open: operation=RP_Monitor_MainFuse1_Open.ClearPrestoredFreezeFrame
          SSCP_GES_MainFuse2_Open: operation=RP_DiagInfo_MainFuse2_Open.GetEventStatus
          SSCP_GEF_MainFuse2_Open: operation=RP_DiagInfo_MainFuse2_Open.GetEventFailed
          SSCP_GET_MainFuse2_Open: operation=RP_DiagInfo_MainFuse2_Open.GetEventTested
          SSCP_GDTC_MainFuse2_Open: operation=RP_DiagInfo_MainFuse2_Open.GetDTCOfEvent
          SSCP_GFDC_MainFuse2_Open: operation=RP_DiagInfo_MainFuse2_Open.GetFaultDetectionCounter
          SSCP_SES_MainFuse2_Open: operation=RP_Monitor_MainFuse2_Open.SetEventStatus
          SSCP_RES_MainFuse2_Open: operation=RP_Monitor_MainFuse2_Open.ResetEventStatus
          SSCP_PFF_MainFuse2_Open: operation=RP_Monitor_MainFuse2_Open.PrestoreFreezeFrame
          SSCP_CPFF_MainFuse2_Open: operation=RP_Monitor_MainFuse2_Open.ClearPrestoredFreezeFrame
          SSCP_GES_VehicleHVInterlockError: operation=RP_DiagInfo_VehicleHVInterlockError.GetEventStatus
          SSCP_GEF_VehicleHVInterlockError: operation=RP_DiagInfo_VehicleHVInterlockError.GetEventFailed
          SSCP_GET_VehicleHVInterlockError: operation=RP_DiagInfo_VehicleHVInterlockError.GetEventTested
          SSCP_GDTC_VehicleHVInterlockError: operation=RP_DiagInfo_VehicleHVInterlockError.GetDTCOfEvent
          SSCP_GFDC_VehicleHVInterlockError: operation=RP_DiagInfo_VehicleHVInterlockError.GetFaultDetectionCounter
          SSCP_SES_VehicleHVInterlockError: operation=RP_Monitor_VehicleHVInterlockError.SetEventStatus
          SSCP_RES_VehicleHVInterlockError: operation=RP_Monitor_VehicleHVInterlockError.ResetEventStatus
          SSCP_PFF_VehicleHVInterlockError: operation=RP_Monitor_VehicleHVInterlockError.PrestoreFreezeFrame
          SSCP_CPFF_VehicleHVInterlockError: operation=RP_Monitor_VehicleHVInterlockError.ClearPrestoredFreezeFrame
          SSCP_GES_BatteryHVInterlockError: operation=RP_DiagInfo_BatteryHVInterlockError.GetEventStatus
          SSCP_GEF_BatteryHVInterlockError: operation=RP_DiagInfo_BatteryHVInterlockError.GetEventFailed
          SSCP_GET_BatteryHVInterlockError: operation=RP_DiagInfo_BatteryHVInterlockError.GetEventTested
          SSCP_GDTC_BatteryHVInterlockError: operation=RP_DiagInfo_BatteryHVInterlockError.GetDTCOfEvent
          SSCP_GFDC_BatteryHVInterlockError: operation=RP_DiagInfo_BatteryHVInterlockError.GetFaultDetectionCounter
          SSCP_SES_BatteryHVInterlockError: operation=RP_Monitor_BatteryHVInterlockError.SetEventStatus
          SSCP_RES_BatteryHVInterlockError: operation=RP_Monitor_BatteryHVInterlockError.ResetEventStatus
          SSCP_PFF_BatteryHVInterlockError: operation=RP_Monitor_BatteryHVInterlockError.PrestoreFreezeFrame
          SSCP_CPFF_BatteryHVInterlockError: operation=RP_Monitor_BatteryHVInterlockError.ClearPrestoredFreezeFrame
          SSCP_GES_BatteryInsulationFault: operation=RP_DiagInfo_BatteryInsulationFault.GetEventStatus
          SSCP_GEF_BatteryInsulationFault: operation=RP_DiagInfo_BatteryInsulationFault.GetEventFailed
          SSCP_GET_BatteryInsulationFault: operation=RP_DiagInfo_BatteryInsulationFault.GetEventTested
          SSCP_GDTC_BatteryInsulationFault: operation=RP_DiagInfo_BatteryInsulationFault.GetDTCOfEvent
          SSCP_GFDC_BatteryInsulationFault: operation=RP_DiagInfo_BatteryInsulationFault.GetFaultDetectionCounter
          SSCP_SES_BatteryInsulationFault: operation=RP_Monitor_BatteryInsulationFault.SetEventStatus
          SSCP_RES_BatteryInsulationFault: operation=RP_Monitor_BatteryInsulationFault.ResetEventStatus
          SSCP_PFF_BatteryInsulationFault: operation=RP_Monitor_BatteryInsulationFault.PrestoreFreezeFrame
          SSCP_CPFF_BatteryInsulationFault: operation=RP_Monitor_BatteryInsulationFault.ClearPrestoredFreezeFrame
          SSCP_GES_VehicleInsulationFault: operation=RP_DiagInfo_VehicleInsulationFault.GetEventStatus
          SSCP_GEF_VehicleInsulationFault: operation=RP_DiagInfo_VehicleInsulationFault.GetEventFailed
          SSCP_GET_VehicleInsulationFault: operation=RP_DiagInfo_VehicleInsulationFault.GetEventTested
          SSCP_GDTC_VehicleInsulationFault: operation=RP_DiagInfo_VehicleInsulationFault.GetDTCOfEvent
          SSCP_GFDC_VehicleInsulationFault: operation=RP_DiagInfo_VehicleInsulationFault.GetFaultDetectionCounter
          SSCP_SES_VehicleInsulationFault: operation=RP_Monitor_VehicleInsulationFault.SetEventStatus
          SSCP_RES_VehicleInsulationFault: operation=RP_Monitor_VehicleInsulationFault.ResetEventStatus
          SSCP_PFF_VehicleInsulationFault: operation=RP_Monitor_VehicleInsulationFault.PrestoreFreezeFrame
          SSCP_CPFF_VehicleInsulationFault: operation=RP_Monitor_VehicleInsulationFault.ClearPrestoredFreezeFrame
          SSCP_GES_Precharge_Resistor_Open: operation=RP_DiagInfo_Precharge_Resistor_Open.GetEventStatus
          SSCP_GEF_Precharge_Resistor_Open: operation=RP_DiagInfo_Precharge_Resistor_Open.GetEventFailed
          SSCP_GET_Precharge_Resistor_Open: operation=RP_DiagInfo_Precharge_Resistor_Open.GetEventTested
          SSCP_GDTC_Precharge_Resistor_Open: operation=RP_DiagInfo_Precharge_Resistor_Open.GetDTCOfEvent
          SSCP_GFDC_Precharge_Resistor_Open: operation=RP_DiagInfo_Precharge_Resistor_Open.GetFaultDetectionCounter
          SSCP_SES_Precharge_Resistor_Open: operation=RP_Monitor_Precharge_Resistor_Open.SetEventStatus
          SSCP_RES_Precharge_Resistor_Open: operation=RP_Monitor_Precharge_Resistor_Open.ResetEventStatus
          SSCP_PFF_Precharge_Resistor_Open: operation=RP_Monitor_Precharge_Resistor_Open.PrestoreFreezeFrame
          SSCP_CPFF_Precharge_Resistor_Open: operation=RP_Monitor_Precharge_Resistor_Open.ClearPrestoredFreezeFrame
          SSCP_GES_Precharge_Error: operation=RP_DiagInfo_Precharge_Error.GetEventStatus
          SSCP_GEF_Precharge_Error: operation=RP_DiagInfo_Precharge_Error.GetEventFailed
          SSCP_GET_Precharge_Error: operation=RP_DiagInfo_Precharge_Error.GetEventTested
          SSCP_GDTC_Precharge_Error: operation=RP_DiagInfo_Precharge_Error.GetDTCOfEvent
          SSCP_GFDC_Precharge_Error: operation=RP_DiagInfo_Precharge_Error.GetFaultDetectionCounter
          SSCP_SES_Precharge_Error: operation=RP_Monitor_Precharge_Error.SetEventStatus
          SSCP_RES_Precharge_Error: operation=RP_Monitor_Precharge_Error.ResetEventStatus
          SSCP_PFF_Precharge_Error: operation=RP_Monitor_Precharge_Error.PrestoreFreezeFrame
          SSCP_CPFF_Precharge_Error: operation=RP_Monitor_Precharge_Error.ClearPrestoredFreezeFrame
          SSCP_GES_PrechargeShortCircuit: operation=RP_DiagInfo_PrechargeShortCircuit.GetEventStatus
          SSCP_GEF_PrechargeShortCircuit: operation=RP_DiagInfo_PrechargeShortCircuit.GetEventFailed
          SSCP_GET_PrechargeShortCircuit: operation=RP_DiagInfo_PrechargeShortCircuit.GetEventTested
          SSCP_GDTC_PrechargeShortCircuit: operation=RP_DiagInfo_PrechargeShortCircuit.GetDTCOfEvent
          SSCP_GFDC_PrechargeShortCircuit: operation=RP_DiagInfo_PrechargeShortCircuit.GetFaultDetectionCounter
          SSCP_SES_PrechargeShortCircuit: operation=RP_Monitor_PrechargeShortCircuit.SetEventStatus
          SSCP_RES_PrechargeShortCircuit: operation=RP_Monitor_PrechargeShortCircuit.ResetEventStatus
          SSCP_PFF_PrechargeShortCircuit: operation=RP_Monitor_PrechargeShortCircuit.PrestoreFreezeFrame
          SSCP_CPFF_PrechargeShortCircuit: operation=RP_Monitor_PrechargeShortCircuit.ClearPrestoredFreezeFrame
          SSCP_GES_CAN_VCU_error: operation=RP_DiagInfo_CAN_VCU_error.GetEventStatus
          SSCP_GEF_CAN_VCU_error: operation=RP_DiagInfo_CAN_VCU_error.GetEventFailed
          SSCP_GET_CAN_VCU_error: operation=RP_DiagInfo_CAN_VCU_error.GetEventTested
          SSCP_GDTC_CAN_VCU_error: operation=RP_DiagInfo_CAN_VCU_error.GetDTCOfEvent
          SSCP_GFDC_CAN_VCU_error: operation=RP_DiagInfo_CAN_VCU_error.GetFaultDetectionCounter
          SSCP_SES_CAN_VCU_error: operation=RP_Monitor_CAN_VCU_error.SetEventStatus
          SSCP_RES_CAN_VCU_error: operation=RP_Monitor_CAN_VCU_error.ResetEventStatus
          SSCP_PFF_CAN_VCU_error: operation=RP_Monitor_CAN_VCU_error.PrestoreFreezeFrame
          SSCP_CPFF_CAN_VCU_error: operation=RP_Monitor_CAN_VCU_error.ClearPrestoredFreezeFrame
          SSCP_GES_CAN_MCUF_Error: operation=RP_DiagInfo_CAN_MCUF_Error.GetEventStatus
          SSCP_GEF_CAN_MCUF_Error: operation=RP_DiagInfo_CAN_MCUF_Error.GetEventFailed
          SSCP_GET_CAN_MCUF_Error: operation=RP_DiagInfo_CAN_MCUF_Error.GetEventTested
          SSCP_GDTC_CAN_MCUF_Error: operation=RP_DiagInfo_CAN_MCUF_Error.GetDTCOfEvent
          SSCP_GFDC_CAN_MCUF_Error: operation=RP_DiagInfo_CAN_MCUF_Error.GetFaultDetectionCounter
          SSCP_SES_CAN_MCUF_Error: operation=RP_Monitor_CAN_MCUF_Error.SetEventStatus
          SSCP_RES_CAN_MCUF_Error: operation=RP_Monitor_CAN_MCUF_Error.ResetEventStatus
          SSCP_PFF_CAN_MCUF_Error: operation=RP_Monitor_CAN_MCUF_Error.PrestoreFreezeFrame
          SSCP_CPFF_CAN_MCUF_Error: operation=RP_Monitor_CAN_MCUF_Error.ClearPrestoredFreezeFrame
          SSCP_GES_CAN_MCUR_Error: operation=RP_DiagInfo_CAN_MCUR_Error.GetEventStatus
          SSCP_GEF_CAN_MCUR_Error: operation=RP_DiagInfo_CAN_MCUR_Error.GetEventFailed
          SSCP_GET_CAN_MCUR_Error: operation=RP_DiagInfo_CAN_MCUR_Error.GetEventTested
          SSCP_GDTC_CAN_MCUR_Error: operation=RP_DiagInfo_CAN_MCUR_Error.GetDTCOfEvent
          SSCP_GFDC_CAN_MCUR_Error: operation=RP_DiagInfo_CAN_MCUR_Error.GetFaultDetectionCounter
          SSCP_SES_CAN_MCUR_Error: operation=RP_Monitor_CAN_MCUR_Error.SetEventStatus
          SSCP_RES_CAN_MCUR_Error: operation=RP_Monitor_CAN_MCUR_Error.ResetEventStatus
          SSCP_PFF_CAN_MCUR_Error: operation=RP_Monitor_CAN_MCUR_Error.PrestoreFreezeFrame
          SSCP_CPFF_CAN_MCUR_Error: operation=RP_Monitor_CAN_MCUR_Error.ClearPrestoredFreezeFrame
          SSCP_GES_CAN_ISG_Error: operation=RP_DiagInfo_CAN_ISG_Error.GetEventStatus
          SSCP_GEF_CAN_ISG_Error: operation=RP_DiagInfo_CAN_ISG_Error.GetEventFailed
          SSCP_GET_CAN_ISG_Error: operation=RP_DiagInfo_CAN_ISG_Error.GetEventTested
          SSCP_GDTC_CAN_ISG_Error: operation=RP_DiagInfo_CAN_ISG_Error.GetDTCOfEvent
          SSCP_GFDC_CAN_ISG_Error: operation=RP_DiagInfo_CAN_ISG_Error.GetFaultDetectionCounter
          SSCP_SES_CAN_ISG_Error: operation=RP_Monitor_CAN_ISG_Error.SetEventStatus
          SSCP_RES_CAN_ISG_Error: operation=RP_Monitor_CAN_ISG_Error.ResetEventStatus
          SSCP_PFF_CAN_ISG_Error: operation=RP_Monitor_CAN_ISG_Error.PrestoreFreezeFrame
          SSCP_CPFF_CAN_ISG_Error: operation=RP_Monitor_CAN_ISG_Error.ClearPrestoredFreezeFrame
          SSCP_GES_CAN_CDU_Error: operation=RP_DiagInfo_CAN_CDU_Error.GetEventStatus
          SSCP_GEF_CAN_CDU_Error: operation=RP_DiagInfo_CAN_CDU_Error.GetEventFailed
          SSCP_GET_CAN_CDU_Error: operation=RP_DiagInfo_CAN_CDU_Error.GetEventTested
          SSCP_GDTC_CAN_CDU_Error: operation=RP_DiagInfo_CAN_CDU_Error.GetDTCOfEvent
          SSCP_GFDC_CAN_CDU_Error: operation=RP_DiagInfo_CAN_CDU_Error.GetFaultDetectionCounter
          SSCP_SES_CAN_CDU_Error: operation=RP_Monitor_CAN_CDU_Error.SetEventStatus
          SSCP_RES_CAN_CDU_Error: operation=RP_Monitor_CAN_CDU_Error.ResetEventStatus
          SSCP_PFF_CAN_CDU_Error: operation=RP_Monitor_CAN_CDU_Error.PrestoreFreezeFrame
          SSCP_CPFF_CAN_CDU_Error: operation=RP_Monitor_CAN_CDU_Error.ClearPrestoredFreezeFrame
          SSCP_GES_CAN_CLM_Error: operation=RP_DiagInfo_CAN_CLM_Error.GetEventStatus
          SSCP_GEF_CAN_CLM_Error: operation=RP_DiagInfo_CAN_CLM_Error.GetEventFailed
          SSCP_GET_CAN_CLM_Error: operation=RP_DiagInfo_CAN_CLM_Error.GetEventTested
          SSCP_GDTC_CAN_CLM_Error: operation=RP_DiagInfo_CAN_CLM_Error.GetDTCOfEvent
          SSCP_GFDC_CAN_CLM_Error: operation=RP_DiagInfo_CAN_CLM_Error.GetFaultDetectionCounter
          SSCP_SES_CAN_CLM_Error: operation=RP_Monitor_CAN_CLM_Error.SetEventStatus
          SSCP_RES_CAN_CLM_Error: operation=RP_Monitor_CAN_CLM_Error.ResetEventStatus
          SSCP_PFF_CAN_CLM_Error: operation=RP_Monitor_CAN_CLM_Error.PrestoreFreezeFrame
          SSCP_CPFF_CAN_CLM_Error: operation=RP_Monitor_CAN_CLM_Error.ClearPrestoredFreezeFrame
          SSCP_GES_CAN_ABM_Error: operation=RP_DiagInfo_CAN_ABM_Error.GetEventStatus
          SSCP_GEF_CAN_ABM_Error: operation=RP_DiagInfo_CAN_ABM_Error.GetEventFailed
          SSCP_GET_CAN_ABM_Error: operation=RP_DiagInfo_CAN_ABM_Error.GetEventTested
          SSCP_GDTC_CAN_ABM_Error: operation=RP_DiagInfo_CAN_ABM_Error.GetDTCOfEvent
          SSCP_GFDC_CAN_ABM_Error: operation=RP_DiagInfo_CAN_ABM_Error.GetFaultDetectionCounter
          SSCP_SES_CAN_ABM_Error: operation=RP_Monitor_CAN_ABM_Error.SetEventStatus
          SSCP_RES_CAN_ABM_Error: operation=RP_Monitor_CAN_ABM_Error.ResetEventStatus
          SSCP_PFF_CAN_ABM_Error: operation=RP_Monitor_CAN_ABM_Error.PrestoreFreezeFrame
          SSCP_CPFF_CAN_ABM_Error: operation=RP_Monitor_CAN_ABM_Error.ClearPrestoredFreezeFrame
          SSCP_GES_CAN_ICM_Error: operation=RP_DiagInfo_CAN_ICM_Error.GetEventStatus
          SSCP_GEF_CAN_ICM_Error: operation=RP_DiagInfo_CAN_ICM_Error.GetEventFailed
          SSCP_GET_CAN_ICM_Error: operation=RP_DiagInfo_CAN_ICM_Error.GetEventTested
          SSCP_GDTC_CAN_ICM_Error: operation=RP_DiagInfo_CAN_ICM_Error.GetDTCOfEvent
          SSCP_GFDC_CAN_ICM_Error: operation=RP_DiagInfo_CAN_ICM_Error.GetFaultDetectionCounter
          SSCP_SES_CAN_ICM_Error: operation=RP_Monitor_CAN_ICM_Error.SetEventStatus
          SSCP_RES_CAN_ICM_Error: operation=RP_Monitor_CAN_ICM_Error.ResetEventStatus
          SSCP_PFF_CAN_ICM_Error: operation=RP_Monitor_CAN_ICM_Error.PrestoreFreezeFrame
          SSCP_CPFF_CAN_ICM_Error: operation=RP_Monitor_CAN_ICM_Error.ClearPrestoredFreezeFrame
          SSCP_GES_CAN_TBOX_Error: operation=RP_DiagInfo_CAN_TBOX_Error.GetEventStatus
          SSCP_GEF_CAN_TBOX_Error: operation=RP_DiagInfo_CAN_TBOX_Error.GetEventFailed
          SSCP_GET_CAN_TBOX_Error: operation=RP_DiagInfo_CAN_TBOX_Error.GetEventTested
          SSCP_GDTC_CAN_TBOX_Error: operation=RP_DiagInfo_CAN_TBOX_Error.GetDTCOfEvent
          SSCP_GFDC_CAN_TBOX_Error: operation=RP_DiagInfo_CAN_TBOX_Error.GetFaultDetectionCounter
          SSCP_SES_CAN_TBOX_Error: operation=RP_Monitor_CAN_TBOX_Error.SetEventStatus
          SSCP_RES_CAN_TBOX_Error: operation=RP_Monitor_CAN_TBOX_Error.ResetEventStatus
          SSCP_PFF_CAN_TBOX_Error: operation=RP_Monitor_CAN_TBOX_Error.PrestoreFreezeFrame
          SSCP_CPFF_CAN_TBOX_Error: operation=RP_Monitor_CAN_TBOX_Error.ClearPrestoredFreezeFrame
          SSCP_GES_CAN_BSM_Error: operation=RP_DiagInfo_CAN_BSM_Error.GetEventStatus
          SSCP_GEF_CAN_BSM_Error: operation=RP_DiagInfo_CAN_BSM_Error.GetEventFailed
          SSCP_GET_CAN_BSM_Error: operation=RP_DiagInfo_CAN_BSM_Error.GetEventTested
          SSCP_GDTC_CAN_BSM_Error: operation=RP_DiagInfo_CAN_BSM_Error.GetDTCOfEvent
          SSCP_GFDC_CAN_BSM_Error: operation=RP_DiagInfo_CAN_BSM_Error.GetFaultDetectionCounter
          SSCP_SES_CAN_BSM_Error: operation=RP_Monitor_CAN_BSM_Error.SetEventStatus
          SSCP_RES_CAN_BSM_Error: operation=RP_Monitor_CAN_BSM_Error.ResetEventStatus
          SSCP_PFF_CAN_BSM_Error: operation=RP_Monitor_CAN_BSM_Error.PrestoreFreezeFrame
          SSCP_CPFF_CAN_BSM_Error: operation=RP_Monitor_CAN_BSM_Error.ClearPrestoredFreezeFrame
          SSCP_GES_CAN_EMS_Error: operation=RP_DiagInfo_CAN_EMS_Error.GetEventStatus
          SSCP_GEF_CAN_EMS_Error: operation=RP_DiagInfo_CAN_EMS_Error.GetEventFailed
          SSCP_GET_CAN_EMS_Error: operation=RP_DiagInfo_CAN_EMS_Error.GetEventTested
          SSCP_GDTC_CAN_EMS_Error: operation=RP_DiagInfo_CAN_EMS_Error.GetDTCOfEvent
          SSCP_GFDC_CAN_EMS_Error: operation=RP_DiagInfo_CAN_EMS_Error.GetFaultDetectionCounter
          SSCP_SES_CAN_EMS_Error: operation=RP_Monitor_CAN_EMS_Error.SetEventStatus
          SSCP_RES_CAN_EMS_Error: operation=RP_Monitor_CAN_EMS_Error.ResetEventStatus
          SSCP_PFF_CAN_EMS_Error: operation=RP_Monitor_CAN_EMS_Error.PrestoreFreezeFrame
          SSCP_CPFF_CAN_EMS_Error: operation=RP_Monitor_CAN_EMS_Error.ClearPrestoredFreezeFrame
          SSCP_GES_PTCAN_BusOff: operation=RP_DiagInfo_PTCAN_BusOff.GetEventStatus
          SSCP_GEF_PTCAN_BusOff: operation=RP_DiagInfo_PTCAN_BusOff.GetEventFailed
          SSCP_GET_PTCAN_BusOff: operation=RP_DiagInfo_PTCAN_BusOff.GetEventTested
          SSCP_GDTC_PTCAN_BusOff: operation=RP_DiagInfo_PTCAN_BusOff.GetDTCOfEvent
          SSCP_GFDC_PTCAN_BusOff: operation=RP_DiagInfo_PTCAN_BusOff.GetFaultDetectionCounter
          SSCP_SES_PTCAN_BusOff: operation=RP_Monitor_PTCAN_BusOff.SetEventStatus
          SSCP_RES_PTCAN_BusOff: operation=RP_Monitor_PTCAN_BusOff.ResetEventStatus
          SSCP_PFF_PTCAN_BusOff: operation=RP_Monitor_PTCAN_BusOff.PrestoreFreezeFrame
          SSCP_CPFF_PTCAN_BusOff: operation=RP_Monitor_PTCAN_BusOff.ClearPrestoredFreezeFrame
          SSCP_GES_LV_UnderVoltage: operation=RP_DiagInfo_LV_UnderVoltage.GetEventStatus
          SSCP_GEF_LV_UnderVoltage: operation=RP_DiagInfo_LV_UnderVoltage.GetEventFailed
          SSCP_GET_LV_UnderVoltage: operation=RP_DiagInfo_LV_UnderVoltage.GetEventTested
          SSCP_GDTC_LV_UnderVoltage: operation=RP_DiagInfo_LV_UnderVoltage.GetDTCOfEvent
          SSCP_GFDC_LV_UnderVoltage: operation=RP_DiagInfo_LV_UnderVoltage.GetFaultDetectionCounter
          SSCP_SES_LV_UnderVoltage: operation=RP_Monitor_LV_UnderVoltage.SetEventStatus
          SSCP_RES_LV_UnderVoltage: operation=RP_Monitor_LV_UnderVoltage.ResetEventStatus
          SSCP_PFF_LV_UnderVoltage: operation=RP_Monitor_LV_UnderVoltage.PrestoreFreezeFrame
          SSCP_CPFF_LV_UnderVoltage: operation=RP_Monitor_LV_UnderVoltage.ClearPrestoredFreezeFrame
          SSCP_GES_LV_OverVoltage: operation=RP_DiagInfo_LV_OverVoltage.GetEventStatus
          SSCP_GEF_LV_OverVoltage: operation=RP_DiagInfo_LV_OverVoltage.GetEventFailed
          SSCP_GET_LV_OverVoltage: operation=RP_DiagInfo_LV_OverVoltage.GetEventTested
          SSCP_GDTC_LV_OverVoltage: operation=RP_DiagInfo_LV_OverVoltage.GetDTCOfEvent
          SSCP_GFDC_LV_OverVoltage: operation=RP_DiagInfo_LV_OverVoltage.GetFaultDetectionCounter
          SSCP_SES_LV_OverVoltage: operation=RP_Monitor_LV_OverVoltage.SetEventStatus
          SSCP_RES_LV_OverVoltage: operation=RP_Monitor_LV_OverVoltage.ResetEventStatus
          SSCP_PFF_LV_OverVoltage: operation=RP_Monitor_LV_OverVoltage.PrestoreFreezeFrame
          SSCP_CPFF_LV_OverVoltage: operation=RP_Monitor_LV_OverVoltage.ClearPrestoredFreezeFrame
